# CY8C5868AXI_LP035 register map
File version: 0.1
Registers are 8-bit, read-write, no defined reset value unless marked. A register's access mark holds for its fields unless they carry their own. Offsets are from the block's base; [hi:lo] are bit positions; 'fields as' and 'values as' point back to an identical list.

## Timer_Line_Begin
Base 0x00000000
0x40006408 Timer_Line_Begin_COUNTER 16-bit — UDB.A0 - Current Down Counter Value
0x40006428 Timer_Line_Begin_PERIOD 16-bit — UDB.D0 - Assigned Period
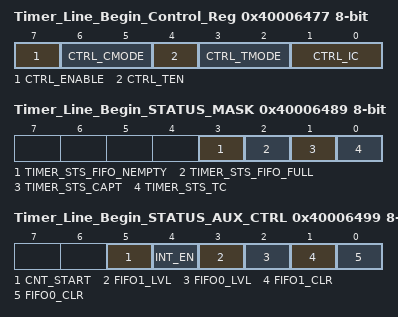
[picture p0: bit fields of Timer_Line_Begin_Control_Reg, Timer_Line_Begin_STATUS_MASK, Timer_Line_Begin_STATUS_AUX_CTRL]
0x40006477 Timer_Line_Begin_Control_Reg — UDB Control Register - Assigned Control Register Value
  [7] CTRL_ENABLE — Enable the Timer
  [6:5] CTRL_CMODE — Capture Mode
  [4] CTRL_TEN — Trigger Enable Bit
  [3:2] CTRL_TMODE — Trigger Mode
  [1:0] CTRL_IC — Interrupt Count
0x40006489 Timer_Line_Begin_STATUS_MASK — UDB Status bits Interrupt Mask Enable Register
  [3] TIMER_STS_FIFO_NEMPTY ro — FIFO Empty status
  [2] TIMER_STS_FIFO_FULL ro — FIFO Full Status
  [1] TIMER_STS_CAPT ro — Enables the Interrupt on Capture
  [0] TIMER_STS_TC ro — Enables the Interrupt on TC
0x40006499 Timer_Line_Begin_STATUS_AUX_CTRL — UDB Auxilliary Control Register
  [5] CNT_START — FIFO0 clear
    0=E_CNT_START0 (Disable counter); 1=E_CNT_START1 (Enable counter)
  [4] INT_EN
    0=E_INT_EN0 (Interrupt disabled); 1=E_INT_EN1 (Interrupt enabled)
  [3] FIFO1_LVL — FIFO level
    0=E_FIFO_LVL_0 (FIFO LVL: input mode: FIFO not full; output mode: FIFO not empty); 1=E_FIFO_LVL_1 (FIFO LVL: input mode: FIFO at least 1/2 empty; output mode: FIFO at least 1/2 full)
  [2] FIFO0_LVL — FIFO level
    values as FIFO1_LVL
  [1] FIFO1_CLR — FIFO1 clear
    0=E_FIFO_CLR_0 (Normal FIFO operation); 1=E_FIFO_CLR_1 (Clear FIFO state)
  [0] FIFO0_CLR — FIFO0 clear
    values as FIFO1_CLR

## Timer_Comp_Ignore_2
Base 0x00000000
0x4000640A Timer_Comp_Ignore_2_COUNTER 16-bit — UDB.A0 - Current Down Counter Value
0x4000642A Timer_Comp_Ignore_2_PERIOD 16-bit — UDB.D0 - Assigned Period
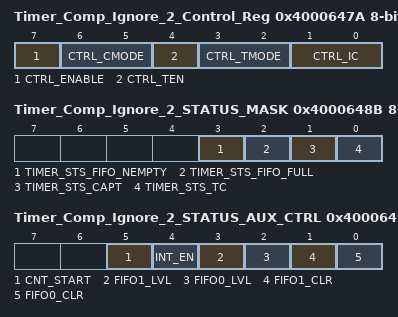
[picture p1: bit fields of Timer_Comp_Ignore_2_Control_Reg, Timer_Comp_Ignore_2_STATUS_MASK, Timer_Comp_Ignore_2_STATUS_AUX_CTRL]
0x4000647A Timer_Comp_Ignore_2_Control_Reg — UDB Control Register - Assigned Control Register Value
  [7] CTRL_ENABLE — Enable the Timer
  [6:5] CTRL_CMODE — Capture Mode
  [4] CTRL_TEN — Trigger Enable Bit
  [3:2] CTRL_TMODE — Trigger Mode
  [1:0] CTRL_IC — Interrupt Count
0x4000648B Timer_Comp_Ignore_2_STATUS_MASK — UDB Status bits Interrupt Mask Enable Register
  [3] TIMER_STS_FIFO_NEMPTY ro — FIFO Empty status
  [2] TIMER_STS_FIFO_FULL ro — FIFO Full Status
  [1] TIMER_STS_CAPT ro — Enables the Interrupt on Capture
  [0] TIMER_STS_TC ro — Enables the Interrupt on TC
0x4000649B Timer_Comp_Ignore_2_STATUS_AUX_CTRL — UDB Auxilliary Control Register
  [5] CNT_START — FIFO0 clear
    0=E_CNT_START0 (Disable counter); 1=E_CNT_START1 (Enable counter)
  [4] INT_EN
    0=E_INT_EN0 (Interrupt disabled); 1=E_INT_EN1 (Interrupt enabled)
  [3] FIFO1_LVL — FIFO level
    0=E_FIFO_LVL_0 (FIFO LVL: input mode: FIFO not full; output mode: FIFO not empty); 1=E_FIFO_LVL_1 (FIFO LVL: input mode: FIFO at least 1/2 empty; output mode: FIFO at least 1/2 full)
  [2] FIFO0_LVL — FIFO level
    values as FIFO1_LVL
  [1] FIFO1_CLR — FIFO1 clear
    0=E_FIFO_CLR_0 (Normal FIFO operation); 1=E_FIFO_CLR_1 (Clear FIFO state)
  [0] FIFO0_CLR — FIFO0 clear
    values as FIFO1_CLR

## Timer_Comp_Ignore_1
Base 0x00000000
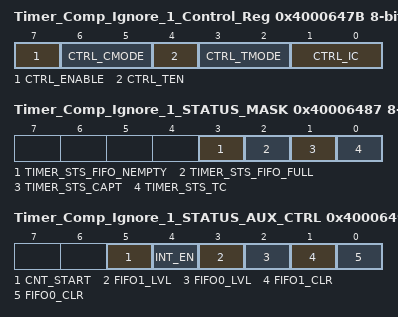
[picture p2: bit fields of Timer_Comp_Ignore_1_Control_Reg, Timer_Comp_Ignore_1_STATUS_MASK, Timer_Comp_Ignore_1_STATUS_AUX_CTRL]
0x4000647B Timer_Comp_Ignore_1_Control_Reg — UDB Control Register - Assigned Control Register Value
  [7] CTRL_ENABLE — Enable the Timer
  [6:5] CTRL_CMODE — Capture Mode
  [4] CTRL_TEN — Trigger Enable Bit
  [3:2] CTRL_TMODE — Trigger Mode
  [1:0] CTRL_IC — Interrupt Count
0x40006487 Timer_Comp_Ignore_1_STATUS_MASK — UDB Status bits Interrupt Mask Enable Register
  [3] TIMER_STS_FIFO_NEMPTY ro — FIFO Empty status
  [2] TIMER_STS_FIFO_FULL ro — FIFO Full Status
  [1] TIMER_STS_CAPT ro — Enables the Interrupt on Capture
  [0] TIMER_STS_TC ro — Enables the Interrupt on TC
0x40006497 Timer_Comp_Ignore_1_STATUS_AUX_CTRL — UDB Auxilliary Control Register
  [5] CNT_START — FIFO0 clear
    0=E_CNT_START0 (Disable counter); 1=E_CNT_START1 (Enable counter)
  [4] INT_EN
    0=E_INT_EN0 (Interrupt disabled); 1=E_INT_EN1 (Interrupt enabled)
  [3] FIFO1_LVL — FIFO level
    0=E_FIFO_LVL_0 (FIFO LVL: input mode: FIFO not full; output mode: FIFO not empty); 1=E_FIFO_LVL_1 (FIFO LVL: input mode: FIFO at least 1/2 empty; output mode: FIFO at least 1/2 full)
  [2] FIFO0_LVL — FIFO level
    values as FIFO1_LVL
  [1] FIFO1_CLR — FIFO1 clear
    0=E_FIFO_CLR_0 (Normal FIFO operation); 1=E_FIFO_CLR_1 (Clear FIFO state)
  [0] FIFO0_CLR — FIFO0 clear
    values as FIFO1_CLR
0x40006506 Timer_Comp_Ignore_1_COUNTER 16-bit — UDB.A0 - Current Down Counter Value
0x40006526 Timer_Comp_Ignore_1_PERIOD 16-bit — UDB.D0 - Assigned Period
